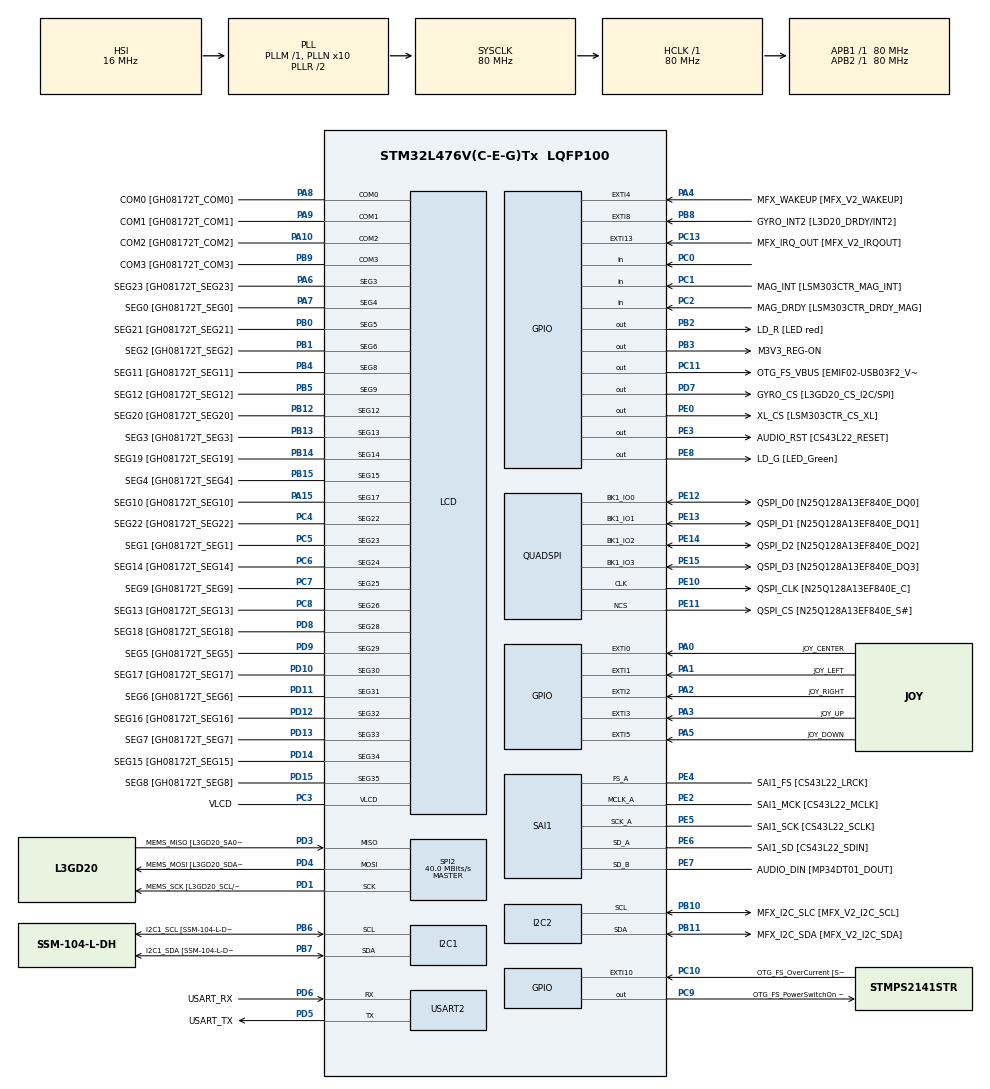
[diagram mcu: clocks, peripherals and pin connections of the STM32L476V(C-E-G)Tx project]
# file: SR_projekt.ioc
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I2C1.Timing=0x10909CEC
I2C2.Timing=0x10909CEC
LCD.Bias=LCD_BIAS_1_3
LCD.BlinkFrequency=LCD_BLINKFREQUENCY_DIV32
LCD.Contrast=LCD_CONTRASTLEVEL_5
LCD.Divider=LCD_DIVIDER_31
LCD.PulseOnDuration=LCD_PULSEONDURATION_4
Mcu.Family=STM32L4
Mcu.Name=STM32L476V(C-E-G)Tx
Mcu.Package=LQFP100
NVIC.EXTI0_IRQn=true\:0\:0\:false\:false\:true\:true\:true\:true
NVIC.EXTI1_IRQn=true\:0\:0\:false\:false\:true\:true\:true\:true
NVIC.EXTI2_IRQn=true\:0\:0\:false\:false\:true\:true\:true\:true
NVIC.EXTI3_IRQn=true\:0\:0\:false\:false\:true\:true\:true\:true
NVIC.EXTI9_5_IRQn=true\:0\:0\:false\:false\:true\:true\:true\:true
NVIC.PriorityGroup=NVIC_PRIORITYGROUP_4
NVIC.RCC_IRQn=true\:0\:0\:false\:false\:true\:true\:false\:true
PA0.GPIO_Label=JOY_CENTER
PA0.GPIO_ModeDefaultEXTI=GPIO_MODE_IT_RISING
PA0.GPIO_PuPd=GPIO_PULLDOWN
PA0.Signal=GPXTI0
PA1.GPIO_Label=JOY_LEFT
PA1.GPIO_ModeDefaultEXTI=GPIO_MODE_IT_RISING
PA1.GPIO_PuPd=GPIO_PULLDOWN
PA1.Signal=GPXTI1
PA10.GPIO_Label=COM2 [GH08172T_COM2]
PA10.GPIO_Mode=GPIO_MODE_AF_PP
PA10.GPIO_PuPd=GPIO_NOPULL
PA10.GPIO_Speed=GPIO_SPEED_FREQ_VERY_HIGH
PA10.Mode=1/4 Duty Cycle
PA10.Signal=LCD_COM2
PA11.GPIO_Label=OTG_FS_DM [EMIF02-USB03F2_D-out]
PA11.GPIO_Mode=GPIO_MODE_AF_PP
PA11.GPIO_PuPd=GPIO_NOPULL
PA11.GPIO_Speed=GPIO_SPEED_FREQ_VERY_HIGH
PA11.Signal=USB_OTG_FS_DM
PA12.GPIO_Label=OTG_FS_DP [EMIF02-USB03F2_D+out]
PA12.GPIO_Mode=GPIO_MODE_AF_PP
PA12.GPIO_PuPd=GPIO_NOPULL
PA12.GPIO_Speed=GPIO_SPEED_FREQ_VERY_HIGH
PA12.Signal=USB_OTG_FS_DP
PA13\ (JTMS-SWDIO).GPIO_Label=SWDIO
PA13\ (JTMS-SWDIO).Mode=Serial_Wire
PA13\ (JTMS-SWDIO).Signal=SYS_JTMS-SWDIO
PA14\ (JTCK-SWCLK).GPIO_Label=SWCLK
PA14\ (JTCK-SWCLK).Mode=Serial_Wire
PA14\ (JTCK-SWCLK).Signal=SYS_JTCK-SWCLK
PA15\ (JTDI).GPIO_Label=SEG10 [GH08172T_SEG10]
PA15\ (JTDI).GPIO_Mode=GPIO_MODE_AF_PP
PA15\ (JTDI).GPIO_PuPd=GPIO_NOPULL
PA15\ (JTDI).GPIO_Speed=GPIO_SPEED_FREQ_VERY_HIGH
PA15\ (JTDI).Mode=SEG17
PA15\ (JTDI).Signal=LCD_SEG17
PA2.GPIO_Label=JOY_RIGHT
PA2.GPIO_ModeDefaultEXTI=GPIO_MODE_IT_RISING
PA2.GPIO_PuPd=GPIO_PULLDOWN
PA2.Signal=GPXTI2
PA3.GPIO_Label=JOY_UP
PA3.GPIO_ModeDefaultEXTI=GPIO_MODE_IT_RISING
PA3.GPIO_PuPd=GPIO_PULLDOWN
PA3.Signal=GPXTI3
PA4.GPIO_Label=MFX_WAKEUP [MFX_V2_WAKEUP]
PA4.GPIO_ModeDefaultEXTI=GPIO_MODE_EVT_RISING
PA4.GPIO_PuPd=GPIO_NOPULL
PA4.Signal=GPXTI4
PA5.GPIO_Label=JOY_DOWN
PA5.GPIO_ModeDefaultEXTI=GPIO_MODE_IT_RISING
PA5.GPIO_PuPd=GPIO_PULLDOWN
PA5.Signal=GPXTI5
PA6.GPIO_Label=SEG23 [GH08172T_SEG23]
PA6.GPIO_Mode=GPIO_MODE_AF_PP
PA6.GPIO_PuPd=GPIO_NOPULL
PA6.GPIO_Speed=GPIO_SPEED_FREQ_VERY_HIGH
PA6.Mode=SEG3
PA6.Signal=LCD_SEG3
PA7.GPIO_Label=SEG0 [GH08172T_SEG0]
PA7.GPIO_Mode=GPIO_MODE_AF_PP
PA7.GPIO_PuPd=GPIO_NOPULL
PA7.GPIO_Speed=GPIO_SPEED_FREQ_VERY_HIGH
PA7.Mode=SEG4
PA7.Signal=LCD_SEG4
PA8.GPIO_Label=COM0 [GH08172T_COM0]
PA8.GPIO_Mode=GPIO_MODE_AF_PP
PA8.GPIO_PuPd=GPIO_NOPULL
PA8.GPIO_Speed=GPIO_SPEED_FREQ_VERY_HIGH
PA8.Mode=1/4 Duty Cycle
PA8.Signal=LCD_COM0
PA9.GPIO_Label=COM1 [GH08172T_COM1]
PA9.GPIO_Mode=GPIO_MODE_AF_PP
PA9.GPIO_PuPd=GPIO_NOPULL
PA9.GPIO_Speed=GPIO_SPEED_FREQ_VERY_HIGH
PA9.Mode=1/4 Duty Cycle
PA9.Signal=LCD_COM1
PB0.GPIO_Label=SEG21 [GH08172T_SEG21]
PB0.GPIO_Mode=GPIO_MODE_AF_PP
PB0.GPIO_PuPd=GPIO_NOPULL
PB0.GPIO_Speed=GPIO_SPEED_FREQ_VERY_HIGH
PB0.Mode=SEG5
PB0.Signal=LCD_SEG5
PB1.GPIO_Label=SEG2 [GH08172T_SEG2]
PB1.GPIO_Mode=GPIO_MODE_AF_PP
PB1.GPIO_PuPd=GPIO_NOPULL
PB1.GPIO_Speed=GPIO_SPEED_FREQ_VERY_HIGH
PB1.Mode=SEG6
PB1.Signal=LCD_SEG6
PB10.GPIO_Label=MFX_I2C_SLC [MFX_V2_I2C_SCL]
PB10.GPIO_Mode=GPIO_MODE_AF_OD
PB10.GPIO_Pu=GPIO_PULLUP
PB10.GPIO_Speed=GPIO_SPEED_FREQ_VERY_HIGH
PB10.Mode=I2C
PB10.Signal=I2C2_SCL
PB11.GPIO_Label=MFX_I2C_SDA [MFX_V2_I2C_SDA]
PB11.GPIO_Mode=GPIO_MODE_AF_OD
PB11.GPIO_Pu=GPIO_PULLUP
PB11.GPIO_Speed=GPIO_SPEED_FREQ_VERY_HIGH
PB11.Mode=I2C
PB11.Signal=I2C2_SDA
PB12.GPIO_Label=SEG20 [GH08172T_SEG20]
PB12.GPIO_Mode=GPIO_MODE_AF_PP
PB12.GPIO_PuPd=GPIO_NOPULL
PB12.GPIO_Speed=GPIO_SPEED_FREQ_VERY_HIGH
PB12.Mode=SEG12
PB12.Signal=LCD_SEG12
PB13.GPIO_Label=SEG3 [GH08172T_SEG3]
PB13.GPIO_Mode=GPIO_MODE_AF_PP
PB13.GPIO_PuPd=GPIO_NOPULL
PB13.GPIO_Speed=GPIO_SPEED_FREQ_VERY_HIGH
PB13.Mode=SEG13
PB13.Signal=LCD_SEG13
PB14.GPIO_Label=SEG19 [GH08172T_SEG19]
PB14.GPIO_Mode=GPIO_MODE_AF_PP
PB14.GPIO_PuPd=GPIO_NOPULL
PB14.GPIO_Speed=GPIO_SPEED_FREQ_VERY_HIGH
PB14.Mode=SEG14
PB14.Signal=LCD_SEG14
PB15.GPIO_Label=SEG4 [GH08172T_SEG4]
PB15.GPIO_Mode=GPIO_MODE_AF_PP
PB15.GPIO_PuPd=GPIO_NOPULL
PB15.GPIO_Speed=GPIO_SPEED_FREQ_VERY_HIGH
PB15.Mode=SEG15
PB15.Signal=LCD_SEG15
PB2.GPIO_Label=LD_R [LED red]
PB2.GPIO_ModeDefaultOutputPP=GPIO_MODE_OUTPUT_PP
PB2.GPIO_PuPd=GPIO_PULLUP
PB2.GPIO_Speed=GPIO_SPEED_FREQ_VERY_HIGH
PB2.Signal=GPIO_Output
PB3\ (JTDO-TRACESWO).GPIO_Label=M3V3_REG-ON
PB3\ (JTDO-TRACESWO).GPIO_ModeDefaultOutputPP=GPIO_MODE_OUTPUT_PP
PB3\ (JTDO-TRACESWO).GPIO_PuPd=GPIO_NOPULL
PB3\ (JTDO-TRACESWO).GPIO_Speed=GPIO_SPEED_FREQ_LOW
PB3\ (JTDO-TRACESWO).Signal=GPIO_Output
PB4\ (NJTRST).GPIO_Label=SEG11 [GH08172T_SEG11]
PB4\ (NJTRST).GPIO_Mode=GPIO_MODE_AF_PP
PB4\ (NJTRST).GPIO_PuPd=GPIO_NOPULL
PB4\ (NJTRST).GPIO_Speed=GPIO_SPEED_FREQ_VERY_HIGH
PB4\ (NJTRST).Mode=SEG8
PB4\ (NJTRST).Signal=LCD_SEG8
PB5.GPIO_Label=SEG12 [GH08172T_SEG12]
PB5.GPIO_Mode=GPIO_MODE_AF_PP
PB5.GPIO_PuPd=GPIO_NOPULL
PB5.GPIO_Speed=GPIO_SPEED_FREQ_VERY_HIGH
PB5.Mode=SEG9
PB5.Signal=LCD_SEG9
PB6.GPIO_FM6=__NULL
PB6.GPIO_Label=I2C1_SCL [SSM-104-L-DH_SCL]
PB6.GPIO_Mode=GPIO_MODE_AF_OD
PB6.GPIO_Pu=GPIO_PULLUP
PB6.GPIO_Speed=GPIO_SPEED_FREQ_VERY_HIGH
PB6.Mode=I2C
PB6.Signal=I2C1_SCL
PB7.GPIO_FM7=__NULL
PB7.GPIO_Label=I2C1_SDA [SSM-104-L-DH_SDA]
PB7.GPIO_Mode=GPIO_MODE_AF_OD
PB7.GPIO_Pu=GPIO_PULLUP
PB7.GPIO_Speed=GPIO_SPEED_FREQ_VERY_HIGH
PB7.Mode=I2C
PB7.Signal=I2C1_SDA
PB8.GPIO_Label=GYRO_INT2 [L3D20_DRDY/INT2]
PB8.GPIO_ModeDefaultEXTI=GPIO_MODE_EVT_RISING
PB8.GPIO_PuPd=GPIO_NOPULL
PB8.Signal=GPXTI8
PB9.GPIO_FM9=__NULL
PB9.GPIO_Label=COM3 [GH08172T_COM3]
PB9.GPIO_Mode=GPIO_MODE_AF_PP
PB9.GPIO_PuPd=GPIO_NOPULL
PB9.GPIO_Speed=GPIO_SPEED_FREQ_VERY_HIGH
PB9.Mode=1/4 Duty Cycle
PB9.Signal=LCD_COM3
PC0.Signal=GPIO_Input
PC1.GPIO_Label=MAG_INT [LSM303CTR_MAG_INT]
PC1.GPIO_Mode=GPIO_MODE_INPUT
PC1.GPIO_PuPd=GPIO_NOPULL
PC1.Signal=GPIO_Input
PC10.GPIO_Label=OTG_FS_OverCurrent [STMPS2141STR_FAULT]
PC10.GPIO_ModeDefaultEXTI=GPIO_MODE_EVT_RISING
PC10.GPIO_PuPd=GPIO_NOPULL
PC10.Signal=GPXTI10
PC11.GPIO_Label=OTG_FS_VBUS [EMIF02-USB03F2_Vbus]
PC11.GPIO_ModeDefaultOutputPP=GPIO_MODE_OUTPUT_PP
PC11.GPIO_PuPd=GPIO_NOPULL
PC11.GPIO_Speed=GPIO_SPEED_FREQ_LOW
PC11.Signal=GPIO_Output
PC13.GPIO_Label=MFX_IRQ_OUT [MFX_V2_IRQOUT]
PC13.GPIO_ModeDefaultEXTI=GPIO_MODE_EVT_RISING
PC13.GPIO_PuPd=GPIO_NOPULL
PC13.Signal=GPXTI13
PC14-OSC32_IN\ (PC14).Mode=LSE-External-Oscillator
PC14-OSC32_IN\ (PC14).Signal=RCC_OSC32_IN
PC15-OSC32_OUT\ (PC15).Mode=LSE-External-Oscillator
PC15-OSC32_OUT\ (PC15).Signal=RCC_OSC32_OUT
PC2.GPIO_Label=MAG_DRDY [LSM303CTR_DRDY_MAG]
PC2.GPIO_Mode=GPIO_MODE_INPUT
PC2.GPIO_PuPd=GPIO_NOPULL
PC2.Signal=GPIO_Input
PC3.GPIO_Label=VLCD
PC3.GPIO_Mode=GPIO_MODE_AF_PP
PC3.GPIO_PuPd=GPIO_NOPULL
PC3.GPIO_Speed=GPIO_SPEED_FREQ_VERY_HIGH
PC3.Mode=1/4 Duty Cycle
PC3.Signal=LCD_VLCD
PC4.GPIO_Label=SEG22 [GH08172T_SEG22]
PC4.GPIO_Mode=GPIO_MODE_AF_PP
PC4.GPIO_PuPd=GPIO_NOPULL
PC4.GPIO_Speed=GPIO_SPEED_FREQ_VERY_HIGH
PC4.Mode=SEG22
PC4.Signal=LCD_SEG22
PC5.GPIO_Label=SEG1 [GH08172T_SEG1]
PC5.GPIO_Mode=GPIO_MODE_AF_PP
PC5.GPIO_PuPd=GPIO_NOPULL
PC5.GPIO_Speed=GPIO_SPEED_FREQ_VERY_HIGH
PC5.Mode=SEG23
PC5.Signal=LCD_SEG23
PC6.GPIO_Label=SEG14 [GH08172T_SEG14]
PC6.GPIO_Mode=GPIO_MODE_AF_PP
PC6.GPIO_PuPd=GPIO_NOPULL
PC6.GPIO_Speed=GPIO_SPEED_FREQ_VERY_HIGH
PC6.Mode=SEG24
PC6.Signal=LCD_SEG24
PC7.GPIO_Label=SEG9 [GH08172T_SEG9]
PC7.GPIO_Mode=GPIO_MODE_AF_PP
PC7.GPIO_PuPd=GPIO_NOPULL
PC7.GPIO_Speed=GPIO_SPEED_FREQ_VERY_HIGH
PC7.Mode=SEG25
PC7.Signal=LCD_SEG25
PC8.GPIO_Label=SEG13 [GH08172T_SEG13]
PC8.GPIO_Mode=GPIO_MODE_AF_PP
PC8.GPIO_PuPd=GPIO_NOPULL
PC8.GPIO_Speed=GPIO_SPEED_FREQ_VERY_HIGH
PC8.Mode=SEG26
PC8.Signal=LCD_SEG26
PC9.GPIO_Label=OTG_FS_PowerSwitchOn [STMPS2141STR_EN]
PC9.GPIO_ModeDefaultOutputPP=GPIO_MODE_OUTPUT_PP
PC9.GPIO_PuPd=GPIO_NOPULL
PC9.GPIO_Speed=GPIO_SPEED_FREQ_LOW
PC9.PinState=GPIO_PIN_SET
PC9.Signal=GPIO_Output
PD1.GPIO_Label=MEMS_SCK [L3GD20_SCL/SPC]
PD1.GPIO_Mode=GPIO_MODE_AF_PP
PD1.GPIO_PuPd=GPIO_NOPULL
PD1.GPIO_Speed=GPIO_SPEED_FREQ_VERY_HIGH
PD1.Mode=Full_Duplex_Master
PD1.Signal=SPI2_SCK
PD10.GPIO_Label=SEG17 [GH08172T_SEG17]
PD10.GPIO_Mode=GPIO_MODE_AF_PP
PD10.GPIO_PuPd=GPIO_NOPULL
PD10.GPIO_Speed=GPIO_SPEED_FREQ_VERY_HIGH
PD10.Mode=SEG30
PD10.Signal=LCD_SEG30
PD11.GPIO_Label=SEG6 [GH08172T_SEG6]
PD11.GPIO_Mode=GPIO_MODE_AF_PP
PD11.GPIO_PuPd=GPIO_NOPULL
PD11.GPIO_Speed=GPIO_SPEED_FREQ_VERY_HIGH
PD11.Mode=SEG31
PD11.Signal=LCD_SEG31
PD12.GPIO_Label=SEG16 [GH08172T_SEG16]
PD12.GPIO_Mode=GPIO_MODE_AF_PP
PD12.GPIO_PuPd=GPIO_NOPULL
PD12.GPIO_Speed=GPIO_SPEED_FREQ_VERY_HIGH
PD12.Mode=SEG32
PD12.Signal=LCD_SEG32
PD13.GPIO_Label=SEG7 [GH08172T_SEG7]
PD13.GPIO_Mode=GPIO_MODE_AF_PP
PD13.GPIO_PuPd=GPIO_NOPULL
PD13.GPIO_Speed=GPIO_SPEED_FREQ_VERY_HIGH
PD13.Mode=SEG33
PD13.Signal=LCD_SEG33
PD14.GPIO_Label=SEG15 [GH08172T_SEG15]
PD14.GPIO_Mode=GPIO_MODE_AF_PP
PD14.GPIO_PuPd=GPIO_NOPULL
PD14.GPIO_Speed=GPIO_SPEED_FREQ_VERY_HIGH
PD14.Mode=SEG34
PD14.Signal=LCD_SEG34
PD15.GPIO_Label=SEG8 [GH08172T_SEG8]
PD15.GPIO_Mode=GPIO_MODE_AF_PP
PD15.GPIO_PuPd=GPIO_NOPULL
PD15.GPIO_Speed=GPIO_SPEED_FREQ_VERY_HIGH
PD15.Mode=SEG35
PD15.Signal=LCD_SEG35
PD3.GPIO_Label=MEMS_MISO [L3GD20_SA0/SDO]
PD3.GPIO_Mode=GPIO_MODE_AF_PP
PD3.GPIO_PuPd=GPIO_NOPULL
PD3.GPIO_Speed=GPIO_SPEED_FREQ_VERY_HIGH
PD3.Mode=Full_Duplex_Master
PD3.Signal=SPI2_MISO
PD4.GPIO_Label=MEMS_MOSI [L3GD20_SDA/SDI/SDO]
PD4.GPIO_Mode=GPIO_MODE_AF_PP
PD4.GPIO_PuPd=GPIO_NOPULL
PD4.GPIO_Speed=GPIO_SPEED_FREQ_VERY_HIGH
PD4.Mode=Full_Duplex_Master
PD4.Signal=SPI2_MOSI
PD5.GPIO_Label=USART_TX
PD5.GPIO_Mode=GPIO_MODE_AF_PP
PD5.GPIO_PuPd=GPIO_PULLUP
PD5.GPIO_Speed=GPIO_SPEED_FREQ_VERY_HIGH
PD5.Mode=Asynchronous
PD5.Signal=USART2_TX
PD6.GPIO_Label=USART_RX
PD6.GPIO_Mode=GPIO_MODE_AF_PP
PD6.GPIO_PuPd=GPIO_PULLUP
PD6.GPIO_Speed=GPIO_SPEED_FREQ_VERY_HIGH
PD6.Mode=Asynchronous
PD6.Signal=USART2_RX
PD7.GPIO_Label=GYRO_CS [L3GD20_CS_I2C/SPI]
PD7.GPIO_ModeDefaultOutputPP=GPIO_MODE_OUTPUT_PP
PD7.GPIO_PuPd=GPIO_NOPULL
PD7.GPIO_Speed=GPIO_SPEED_FREQ_VERY_HIGH
PD7.Signal=GPIO_Output
PD8.GPIO_Label=SEG18 [GH08172T_SEG18]
PD8.GPIO_Mode=GPIO_MODE_AF_PP
PD8.GPIO_PuPd=GPIO_NOPULL
PD8.GPIO_Speed=GPIO_SPEED_FREQ_VERY_HIGH
PD8.Mode=SEG28
PD8.Signal=LCD_SEG28
PD9.GPIO_Label=SEG5 [GH08172T_SEG5]
PD9.GPIO_Mode=GPIO_MODE_AF_PP
PD9.GPIO_PuPd=GPIO_NOPULL
PD9.GPIO_Speed=GPIO_SPEED_FREQ_VERY_HIGH
PD9.Mode=SEG29
PD9.Signal=LCD_SEG29
PE0.GPIO_Label=XL_CS [LSM303CTR_CS_XL]
PE0.GPIO_ModeDefaultOutputPP=GPIO_MODE_OUTPUT_PP
PE0.GPIO_PuPd=GPIO_NOPULL
PE0.GPIO_Speed=GPIO_SPEED_FREQ_LOW
PE0.Signal=GPIO_Output
PE10.GPIO_Label=QSPI_CLK [N25Q128A13EF840E_C]
PE10.GPIO_Mode=GPIO_MODE_AF_PP
PE10.GPIO_PuPd=GPIO_NOPULL
PE10.GPIO_Speed=GPIO_SPEED_FREQ_VERY_HIGH
PE10.Mode=Single Bank
PE10.Signal=QUADSPI_CLK
PE11.GPIO_Label=QSPI_CS [N25Q128A13EF840E_S\#]
PE11.GPIO_Mode=GPIO_MODE_AF_PP
PE11.GPIO_PuPd=GPIO_PULLUP
PE11.GPIO_Speed=GPIO_SPEED_FREQ_VERY_HIGH
PE11.Mode=Single Bank
PE11.Signal=QUADSPI_NCS
PE12.GPIO_Label=QSPI_D0 [N25Q128A13EF840E_DQ0]
PE12.GPIO_Mode=GPIO_MODE_AF_PP
PE12.GPIO_PuPd=GPIO_NOPULL
PE12.GPIO_Speed=GPIO_SPEED_FREQ_VERY_HIGH
PE12.Mode=Single Bank
PE12.Signal=QUADSPI_BK1_IO0
PE13.GPIO_Label=QSPI_D1 [N25Q128A13EF840E_DQ1]
PE13.GPIO_Mode=GPIO_MODE_AF_PP
PE13.GPIO_PuPd=GPIO_NOPULL
PE13.GPIO_Speed=GPIO_SPEED_FREQ_VERY_HIGH
PE13.Mode=Single Bank
PE13.Signal=QUADSPI_BK1_IO1
PE14.GPIO_Label=QSPI_D2 [N25Q128A13EF840E_DQ2]
PE14.GPIO_Mode=GPIO_MODE_AF_PP
PE14.GPIO_PuPd=GPIO_NOPULL
PE14.GPIO_Speed=GPIO_SPEED_FREQ_VERY_HIGH
PE14.Mode=Single Bank
PE14.Signal=QUADSPI_BK1_IO2
PE15.GPIO_Label=QSPI_D3 [N25Q128A13EF840E_DQ3]
PE15.GPIO_Mode=GPIO_MODE_AF_PP
PE15.GPIO_PuPd=GPIO_NOPULL
PE15.GPIO_Speed=GPIO_SPEED_FREQ_VERY_HIGH
PE15.Mode=Single Bank
PE15.Signal=QUADSPI_BK1_IO3
PE2.GPIO_Label=SAI1_MCK [CS43L22_MCLK]
PE2.GPIO_Mode=GPIO_MODE_AF_PP
PE2.GPIO_PuPd=GPIO_NOPULL
PE2.GPIO_Speed=GPIO_SPEED_FREQ_VERY_HIGH
PE2.Mode=SAI_A_MasterWithClock
PE2.Signal=SAI1_MCLK_A
PE3.GPIO_Label=AUDIO_RST [CS43L22_RESET]
PE3.GPIO_ModeDefaultOutputPP=GPIO_MODE_OUTPUT_PP
PE3.GPIO_PuPd=GPIO_NOPULL
PE3.GPIO_Speed=GPIO_SPEED_FREQ_HIGH
PE3.Signal=GPIO_Output
PE4.GPIO_Label=SAI1_FS [CS43L22_LRCK]
PE4.GPIO_Mode=GPIO_MODE_AF_PP
PE4.GPIO_PuPd=GPIO_NOPULL
PE4.GPIO_Speed=GPIO_SPEED_FREQ_VERY_HIGH
PE4.Mode=SAI_A_MasterWithClock
PE4.Signal=SAI1_FS_A
PE5.GPIO_Label=SAI1_SCK [CS43L22_SCLK]
PE5.GPIO_Mode=GPIO_MODE_AF_PP
PE5.GPIO_PuPd=GPIO_NOPULL
PE5.GPIO_Speed=GPIO_SPEED_FREQ_VERY_HIGH
PE5.Mode=SAI_A_MasterWithClock
PE5.Signal=SAI1_SCK_A
PE6.GPIO_Label=SAI1_SD [CS43L22_SDIN]
PE6.GPIO_Mode=GPIO_MODE_AF_PP
PE6.GPIO_PuPd=GPIO_NOPULL
PE6.GPIO_Speed=GPIO_SPEED_FREQ_VERY_HIGH
PE6.Mode=SAI_A_MasterWithClock
PE6.Signal=SAI1_SD_A
PE7.GPIO_Label=AUDIO_DIN [MP34DT01_DOUT]
PE7.GPIO_Mode=GPIO_MODE_AF_PP
PE7.GPIO_PuPd=GPIO_NOPULL
PE7.GPIO_Speed=GPIO_SPEED_FREQ_VERY_HIGH
PE7.Mode=SAI_B_SyncSlave
PE7.Signal=SAI1_SD_B
PE8.GPIO_Label=LD_G [LED_Green]
PE8.GPIO_ModeDefaultOutputPP=GPIO_MODE_OUTPUT_PP
PE8.GPIO_PuPd=GPIO_PULLUP
PE8.GPIO_Speed=GPIO_SPEED_FREQ_VERY_HIGH
PE8.Signal=GPIO_Output
PE9.GPIO_Label=AUDIO_CLK [MP34DT01_CLK]
PE9.GPIO_Mode=GPIO_MODE_AF_PP
PE9.GPIO_PuPd=GPIO_NOPULL
PE9.GPIO_Speed=GPIO_SPEED_FREQ_LOW
PE9.Signal=SAI1_FS_B
PH0-OSC_IN\ (PH0).Mode=HSE-External-Oscillator
PH0-OSC_IN\ (PH0).Signal=RCC_OSC_IN
PH1-OSC_OUT\ (PH1).Mode=HSE-External-Oscillator
PH1-OSC_OUT\ (PH1).Signal=RCC_OSC_OUT
ProjectManager.HeapSize=0x200
ProjectManager.StackSize=0x400
ProjectManager.TargetToolchain=STM32CubeIDE
QUADSPI.ClockPrescaler=1
QUADSPI.FifoThreshold=4
QUADSPI.FlashSize=24
QUADSPI.FlashSize-Single\ Bank=16
QUADSPI.SampleShifting=QSPI_SAMPLE_SHIFTING_HALFCYCLE
RCC.ADCFreq_Value=64000000
RCC.AHBFreq_Value=80000000
RCC.APB1Freq_Value=80000000
RCC.APB1TimFreq_Value=80000000
RCC.APB2Freq_Value=80000000
RCC.APB2TimFreq_Value=80000000
RCC.CortexFreq_Value=80000000
RCC.HCLKFreq_Value=80000000
RCC.HSE_VALUE=8000000
RCC.HSI_VALUE=16000000
RCC.MSI_VALUE=4000000
RCC.PLLN=10
RCC.PLLSourceVirtual=RCC_PLLSOURCE_HSI
RCC.PREFETCH_ENABLE=1
RCC.RTCClockSelection=RCC_RTCCLKSOURCE_LSE
RCC.SYSCLKFreq_VALUE=80000000
RCC.SYSCLKSource=RCC_SYSCLKSOURCE_PLLCLK
RCC.USBFreq_Value=64000000
RCC.VCOOutputFreq_Value=160000000
RTC.Date=19
RTC.Month=RTC_MONTH_MARCH
RTC.WeekDay=RTC_WEEKDAY_SATURDAY
RTC.Year=22
SAI1.ErrorAudioFreq-SAI_A_MasterWithClock=-62.79 %
SAI1.Instance-SAI_A_MasterWithClock=SAI$Index_Block_A
SAI1.Instance-SAI_B_SyncSlave=SAI$Index_Block_B
SAI1.MClockEnable-SAI_A_MasterWithClock=SAI_MASTERCLOCK_ENABLE
SAI1.RealAudioFreq-SAI_A_MasterWithClock=71.428 KHz
SAI1.Synchro-SAI_B_SyncSlave=SAI_SYNCHRONOUS
SAI1.VirtualMode-SAI_A_MasterWithClock=VM_MASTER
SAI1.VirtualMode-SAI_B_SyncSlave=VM_SLAVE
SPI2.BaudRatePrescaler=SPI_BAUDRATEPRESCALER_2
SPI2.CalculateBaudRate=40.0 MBits/s
SPI2.Direction=SPI_DIRECTION_2LINES
SPI2.Mode=SPI_MODE_MASTER
SPI2.VirtualType=VM_MASTER
USART2.VirtualMode-Asynchronous=VM_ASYNC
VP_IWDG_VS_IWDG.Mode=IWDG_Activate
VP_RTC_VS_RTC_Activate.Mode=RTC_Enabled
VP_RTC_VS_RTC_Calendar.Mode=RTC_Calendar
board=STM32L476G-DISCO

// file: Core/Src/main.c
/* USER CODE BEGIN Header */
/**
 ******************************************************************************
 * @file           : main.c
 * @brief          : Main program body
 ******************************************************************************
 * @attention
 *
 * Copyright (c) 2022 STMicroelectronics.
 * All rights reserved.
 *
 * This software is licensed under terms that can be found in the LICENSE file
 * in the root directory of this software component.
 * If no LICENSE file comes with this software, it is provided AS-IS.
 *
 ******************************************************************************
 */
/* USER CODE END Header */
#include "main.h"
#include "i2c.h"
#include "iwdg.h"
#include "lcd.h"
#include "quadspi.h"
#include "rtc.h"
#include "sai.h"
#include "spi.h"
#include "usart.h"
#include "gpio.h"

/* USER CODE BEGIN Includes */
#include "stdbool.h"
#include "string.h"
#include "lfs.h"
#include "stm32l476g_discovery_qspi.h"
#include "lsm303c.h"
#include "math.h"
#include <stdio.h>
#include <stdbool.h>
/* USER CODE END Includes */

/* USER CODE BEGIN PV */
lfs_t lfs;
lfs_file_t file;
volatile JOYState_TypeDef joy_state = JOY_NONE;
volatile FlagStatus KeyPressed = RESET;
/* USER CODE END PV */

void SystemClock_Config(void);
void PeriphCommonClock_Config(void);
/* USER CODE BEGIN PFP */
void HAL_GPIO_EXTI_Callback(uint16_t GPIO_Pin);
int block_device_read(const struct lfs_config *c, lfs_block_t block, lfs_off_t off, void *buffer, lfs_size_t size);
int block_device_prog(const struct lfs_config *c, lfs_block_t block, lfs_off_t off, const void *buffer, lfs_size_t size);
int block_device_erase(const struct lfs_config *c, lfs_block_t block);
int block_device_sync(const struct lfs_config *c);

void readFile(lfs_t *lfs, lfs_file_t *file, const char *path, void *buffer, lfs_size_t size);
void writeFile(lfs_t *lfs, lfs_file_t *file, const char *path, const void *buffer, lfs_size_t size);
static int traverse_df_cb(void *p, lfs_block_t block);
static int df(void);
int16_t GetTemperature();
void initMagneto();
void initFileSystem(int *number_of_records, uint32_t *delay_between_saves);
float convertRegDataToTemperature(int16_t value);
float getTemperatureCelsius();
void menu(int *menu_position, char *text, int *menu_select, int *i, bool erase_flag);
void menuUserView(int choose, char *text);
void setDateUserView(int choose, RTC_TimeTypeDef time, RTC_DateTypeDef date, char *text);
void changeDateDown(int choose, RTC_TimeTypeDef *time, RTC_DateTypeDef *date);
void changeDateUp(int choose, RTC_TimeTypeDef *time, RTC_DateTypeDef *date);
void timeUserView(int choose, RTC_TimeTypeDef *time, char *text);
void changeTimeDown(int choose, RTC_TimeTypeDef *time);
void changeTimeUp(int choose, RTC_TimeTypeDef *time);
void setDelayBetweenSaves(uint32_t *delay_between_saves, RTC_TimeTypeDef *time);
bool eraseAllData(int *number_of_records, int *read_record_number, uint32_t *delay_between_saves);
void viewActualData(RTC_TimeTypeDef *RtcTime, RTC_DateTypeDef *RtcDate, char *text);
void saveData(RTC_TimeTypeDef *RtcTime, RTC_DateTypeDef *RtcDate, int *number_of_records);
void setTimeBetweenSaves(RTC_TimeTypeDef *time, uint32_t delay);
/* USER CODE END PFP */

/* USER CODE BEGIN 0 */
const struct lfs_config cfg = {
    // block device operations
    .read = block_device_read,
    .prog = block_device_prog,
    .erase = block_device_erase,
    .sync = block_device_sync,

    // block device configuration
    .read_size = 16,
    .prog_size = 16,
    .block_size = 4096,
    .block_count = 4096,
    .cache_size = 16,
    .lookahead_size = 16,
    .block_cycles = 500,
};
/* USER CODE END 0 */

int main(void)
{
    /* USER CODE BEGIN 1 */
    uint32_t last_ms = HAL_GetTick(), last_ms_save = last_ms, now = last_ms, delay_text_scroll = 200, delay_between_saves = 3600000; // delays in ms; delay between saves is one hour
    int i = 0, menu_position = 0, menu_select = 0, set_time_tmp = -1, number_of_records = 0, read_record_number = 0;
    char text[60], display[6], record_file_name[15];
    bool erase_flag = false, new_data = false;
    RTC_TimeTypeDef RtcTime = {0}, new_time = {0}, time_between_saves = {0};
    RTC_DateTypeDef RtcDate = {0}, new_date = {0};
    /* USER CODE END 1 */

    /* MCU Configuration--------------------------------------------------------*/

    /* Reset of all peripherals, Initializes the Flash interface and the Systick. */
    HAL_Init();

    /* Configure the system clock */
    SystemClock_Config();

    /* Configure the peripherals common clocks */
    PeriphCommonClock_Config();

    /* Initialize all configured peripherals */
    MX_GPIO_Init();
    MX_I2C1_Init();
    MX_I2C2_Init();
    // MX_LCD_Init();
    // MX_QUADSPI_Init();
    MX_SAI1_Init();
    MX_SPI2_Init();
    MX_USART2_UART_Init();
    MX_RTC_Init();
    MX_IWDG_Init();
    /* USER CODE BEGIN 2 */
    BSP_LCD_GLASS_Init();
    BSP_QSPI_Init();
    initMagneto();
    initFileSystem(&number_of_records, &delay_between_saves);
    HAL_RTC_GetTime(&hrtc, &RtcTime, RTC_FORMAT_BIN);
    HAL_RTC_GetDate(&hrtc, &RtcDate, RTC_FORMAT_BIN);

    read_record_number = number_of_records;
    setTimeBetweenSaves(&time_between_saves, delay_between_saves);

    sprintf(text, "UZYJ JOYSTICKA ABY NAWIGOWAC      ");
    /* USER CODE END 2 */

    /* Infinite loop */
    /* USER CODE BEGIN WHILE */
    while (1)
    {
        now = HAL_GetTick();

        if (KeyPressed)
        {
            menu(&menu_position, text, &menu_select, &i, erase_flag);
        }

        if (i <= strlen(text))
        {
            if (now - last_ms >= delay_text_scroll)
            {
                last_ms = now;

                switch (menu_select)
                {
                case 1:
                    viewActualData(&RtcTime, &RtcDate, text);
                    break;
                case 2:
                    if (number_of_records)
                    {
                        if (new_data)
                        {
                            i = 0;
                            new_data = false;
                        }
                        switch (joy_state)
                        {
                        case JOY_RIGHT:
                            if (!erase_flag)
                            {
                                erase_flag = true;
                                i = 0;
                            }

                            break;
                        case JOY_LEFT:
                            if (erase_flag)
                            {
                                erase_flag = false;
                                i = 0;
                            }
                            break;
                        case JOY_SEL:
                            if (erase_flag)
                            {
                                erase_flag = eraseAllData(&number_of_records, &read_record_number, &delay_between_saves);
                            }

                            break;
                        case JOY_UP:
                            read_record_number++;
                            if (read_record_number > number_of_records)
                            {
                                read_record_number = 1;
                            }
                            i = 0;
                            break;
                        case JOY_DOWN:
                            read_record_number--;
                            if (read_record_number < 1)
                            {
                                read_record_number = number_of_records;
                            }
                            i = 0;
                            break;
                        default:
                            break;
                        }
                        joy_state = JOY_NONE;
                        if (!erase_flag)
                        {
                            sprintf(record_file_name, "record%d", read_record_number);
                            readFile(&lfs, &file, record_file_name, &text, sizeof(text));
                        }
                        else
                        {
                            sprintf(text, "POTWIERDZ USUNIECIE DANYCH      ");
                        }
                    }
                    else
                    {
                        new_data = true;
                        sprintf(text, "BRAK ZAPISANYCH DANYCH      ");
                    }
                    break;
                case 3:
                    switch (joy_state)
                    {
                    case JOY_SEL:
                        set_time_tmp++;
                        break;
                    case JOY_UP:
                        changeDateUp(set_time_tmp, &new_time, &new_date);
                        break;
                    case JOY_DOWN:
                        changeDateDown(set_time_tmp, &new_time, &new_date);
                        break;
                    default:
                        break;
                    }
                    setDateUserView(set_time_tmp, new_time, new_date, text);
                    if (set_time_tmp <= 5)
                    {
                        joy_state = JOY_NONE;
                    }
                    else
                    {
                        HAL_RTC_SetTime(&hrtc, &new_time, RTC_FORMAT_BIN);
                        HAL_RTC_SetDate(&hrtc, &new_date, RTC_FORMAT_BIN);
                        joy_state = JOY_LEFT;
                        KeyPressed = SET;
                    }
                    break;
                case 4:
                    switch (joy_state)
                    {
                    case JOY_SEL:
                        set_time_tmp++;
                        if (time_between_saves.Hours == 0 && time_between_saves.Minutes == 0 && time_between_saves.Seconds == 0 && set_time_tmp == 2)
                        {
                            time_between_saves.Seconds = 1;
                        }
                        break;
                    case JOY_UP:
                        changeTimeUp(set_time_tmp, &time_between_saves);
                        break;
                    case JOY_DOWN:
                        changeTimeDown(set_time_tmp, &time_between_saves);
                        break;
                    default:
                        break;
                    }

                    timeUserView(set_time_tmp, &time_between_saves, text);

                    if (set_time_tmp <= 2)
                    {
                        joy_state = JOY_NONE;
                    }
                    else
                    {
                        setDelayBetweenSaves(&delay_between_saves, &time_between_saves);
                        joy_state = JOY_LEFT;
                        KeyPressed = SET;
                    }
                    break;
                default:
                    read_record_number = number_of_records;
                    set_time_tmp = -1;
                    new_time = RtcTime;
                    new_date = RtcDate;
                    menuUserView(menu_position, text);
                    break;
                }

                if (menu_select < 3)
                {
                    for (int j = i - 6; j < i; j++)
                    {
                        if (j < 0)
                        {
                            display[j - i + 6] = text[strlen(text) + j];
                        }
                        else
                        {
                            display[j - i + 6] = text[j];
                        }
                    }
                    i++;
                    BSP_LCD_GLASS_Clear();
                    BSP_LCD_GLASS_DisplayString((uint8_t *)display);
                }
                else
                {
                    BSP_LCD_GLASS_Clear();
                    BSP_LCD_GLASS_DisplayString((uint8_t *)text);
                }
                BSP_LCD_GLASS_DisplayBar(LCD_BAR_3 >> (menu_position - 1));
            }

            if (now - last_ms_save >= delay_between_saves)
            {
                last_ms_save = now;
                saveData(&RtcTime, &RtcDate, &number_of_records);
            }
        }
        else
        {
            i = 0;
        }

        HAL_IWDG_Refresh(&hiwdg);
        /* USER CODE END WHILE */

    }
}

void SystemClock_Config(void)
{
    RCC_OscInitTypeDef RCC_OscInitStruct = {0};
    RCC_ClkInitTypeDef RCC_ClkInitStruct = {0};

    /** Configure the main internal regulator output voltage
     */
    if (HAL_PWREx_ControlVoltageScaling(PWR_REGULATOR_VOLTAGE_SCALE1) != HAL_OK)
    {
        Error_Handler();
    }

    /** Configure LSE Drive Capability
     */
    HAL_PWR_EnableBkUpAccess();
    __HAL_RCC_LSEDRIVE_CONFIG(RCC_LSEDRIVE_LOW);

    /** Initializes the RCC Oscillators according to the specified parameters
     * in the RCC_OscInitTypeDef structure.
     */
    RCC_OscInitStruct.OscillatorType = RCC_OSCILLATORTYPE_HSI | RCC_OSCILLATORTYPE_LSI | RCC_OSCILLATORTYPE_LSE;
    RCC_OscInitStruct.LSEState = RCC_LSE_ON;
    RCC_OscInitStruct.HSIState = RCC_HSI_ON;
    RCC_OscInitStruct.HSICalibrationValue = RCC_HSICALIBRATION_DEFAULT;
    RCC_OscInitStruct.LSIState = RCC_LSI_ON;
    RCC_OscInitStruct.PLL.PLLState = RCC_PLL_ON;
    RCC_OscInitStruct.PLL.PLLSource = RCC_PLLSOURCE_HSI;
    RCC_OscInitStruct.PLL.PLLM = 1;
    RCC_OscInitStruct.PLL.PLLN = 10;
    RCC_OscInitStruct.PLL.PLLP = RCC_PLLP_DIV7;
    RCC_OscInitStruct.PLL.PLLQ = RCC_PLLQ_DIV2;
    RCC_OscInitStruct.PLL.PLLR = RCC_PLLR_DIV2;
    if (HAL_RCC_OscConfig(&RCC_OscInitStruct) != HAL_OK)
    {
        Error_Handler();
    }

    /** Initializes the CPU, AHB and APB buses clocks
     */
    RCC_ClkInitStruct.ClockType = RCC_CLOCKTYPE_HCLK | RCC_CLOCKTYPE_SYSCLK | RCC_CLOCKTYPE_PCLK1 | RCC_CLOCKTYPE_PCLK2;
    RCC_ClkInitStruct.SYSCLKSource = RCC_SYSCLKSOURCE_PLLCLK;
    RCC_ClkInitStruct.AHBCLKDivider = RCC_SYSCLK_DIV1;
    RCC_ClkInitStruct.APB1CLKDivider = RCC_HCLK_DIV1;
    RCC_ClkInitStruct.APB2CLKDivider = RCC_HCLK_DIV1;

    if (HAL_RCC_ClockConfig(&RCC_ClkInitStruct, FLASH_LATENCY_4) != HAL_OK)
    {
        Error_Handler();
    }
}

void PeriphCommonClock_Config(void)
{
    RCC_PeriphCLKInitTypeDef PeriphClkInit = {0};

    /** Initializes the peripherals clock
     */
    PeriphClkInit.PeriphClockSelection = RCC_PERIPHCLK_SAI1;
    PeriphClkInit.Sai1ClockSelection = RCC_SAI1CLKSOURCE_PLLSAI1;
    PeriphClkInit.PLLSAI1.PLLSAI1Source = RCC_PLLSOURCE_HSI;
    PeriphClkInit.PLLSAI1.PLLSAI1M = 1;
    PeriphClkInit.PLLSAI1.PLLSAI1N = 8;
    PeriphClkInit.PLLSAI1.PLLSAI1P = RCC_PLLP_DIV7;
    PeriphClkInit.PLLSAI1.PLLSAI1Q = RCC_PLLQ_DIV2;
    PeriphClkInit.PLLSAI1.PLLSAI1R = RCC_PLLR_DIV2;
    PeriphClkInit.PLLSAI1.PLLSAI1ClockOut = RCC_PLLSAI1_SAI1CLK;
    if (HAL_RCCEx_PeriphCLKConfig(&PeriphClkInit) != HAL_OK)
    {
        Error_Handler();
    }
}

/* USER CODE BEGIN 4 */
void HAL_GPIO_EXTI_Callback(uint16_t GPIO_Pin)
{
    if ((GPIO_Pin & (DOWN_JOY_PIN | UP_JOY_PIN | SEL_JOY_PIN | RIGHT_JOY_PIN | LEFT_JOY_PIN)) != RESET)
    {
        KeyPressed = SET;

        switch (GPIO_Pin)
        {
        case DOWN_JOY_PIN:
            joy_state = JOY_DOWN;
            break;
        case UP_JOY_PIN:
            joy_state = JOY_UP;
            break;
        case SEL_JOY_PIN:
            joy_state = JOY_SEL;
            break;
        case RIGHT_JOY_PIN:
            joy_state = JOY_RIGHT;
            break;
        case LEFT_JOY_PIN:
            joy_state = JOY_LEFT;
            break;
        }
    }
}

int block_device_read(const struct lfs_config *c, lfs_block_t block, lfs_off_t off, void *buffer, lfs_size_t size)
{
    BSP_QSPI_Read((uint8_t *)buffer, (block * c->block_size + off), size);
    return 0;
}

int block_device_prog(const struct lfs_config *c, lfs_block_t block, lfs_off_t off, const void *buffer, lfs_size_t size)
{
    BSP_QSPI_Write((uint8_t *)buffer, (block * c->block_size + off), size);
    return 0;
}

int block_device_erase(const struct lfs_config *c, lfs_block_t block)
{
    BSP_QSPI_Erase_Block(block * c->block_size);
    return 0;
}

int block_device_sync(const struct lfs_config *c)
{
    return 0;
}

void readFile(lfs_t *lfs, lfs_file_t *file, const char *path, void *buffer, lfs_size_t size)
{
    lfs_file_open(lfs, file, path, LFS_O_RDWR | LFS_O_CREAT);
    lfs_file_read(lfs, file, buffer, size);
    lfs_file_close(lfs, file);
}

void writeFile(lfs_t *lfs, lfs_file_t *file, const char *path, const void *buffer, lfs_size_t size)
{
    lfs_file_open(lfs, file, path, LFS_O_RDWR | LFS_O_CREAT);
    lfs_file_write(lfs, file, buffer, size);
    lfs_file_close(lfs, file);
}

static int traverse_df_cb(void *p, lfs_block_t block)
{
    uint32_t *nb = p;
    *nb += 1;
    return 0;
}

static int df(void)
{
    int err;

    uint32_t df_nballocatedblock = 0;
    err = lfs_fs_traverse(&lfs, traverse_df_cb, &df_nballocatedblock);
    if (err < 0)
    {
        return err;
    }

    uint32_t available = cfg.block_count * cfg.block_size - df_nballocatedblock * cfg.block_size;

    return available;
}

int16_t GetTemperature()
{
    int8_t buffer[2];
    buffer[0] = MAGNETO_IO_Read(LSM303C_TEMP_OUT_L_M);
    buffer[1] = MAGNETO_IO_Read(LSM303C_TEMP_OUT_H_M);

    int16_t temp = ((int16_t)((uint16_t)buffer[1] << 8) + buffer[0]);
    return temp;
}

void initMagneto()
{
    MAGNETO_IO_Init();
    MAGNETO_IO_Write(LSM303C_CTRL_REG1_M, LSM303C_MAG_TEMPSENSOR_ENABLE | LSM303C_MAG_OM_XY_ULTRAHIGH | LSM303C_MAG_ODR_40_HZ);
    MAGNETO_IO_Write(LSM303C_CTRL_REG2_M, LSM303C_MAG_FS_16_GA | LSM303C_MAG_REBOOT_DEFAULT | LSM303C_MAG_SOFT_RESET_DEFAULT);
    MAGNETO_IO_Write(LSM303C_CTRL_REG3_M, 0x84);
    MAGNETO_IO_Write(LSM303C_CTRL_REG4_M, LSM303C_MAG_OM_Z_ULTRAHIGH | LSM303C_MAG_BLE_LSB);
    MAGNETO_IO_Write(LSM303C_CTRL_REG5_M, LSM303C_MAG_BDU_CONTINUOUS);
}

void initFileSystem(int *number_of_records, uint32_t *delay_between_saves)
{
    if (!lfs_mount(&lfs, &cfg))
    {
        BSP_LCD_GLASS_DisplayString((uint8_t *)"FS OK");
        readFile(&lfs, &file, "number_of_records", number_of_records, sizeof((*number_of_records)));
        readFile(&lfs, &file, "delay_between_saves", delay_between_saves, sizeof((*delay_between_saves)));
    }
    else
    {
        BSP_LCD_GLASS_DisplayString((uint8_t *)"FS NEW");
        lfs_format(&lfs, &cfg);
        lfs_mount(&lfs, &cfg);
        writeFile(&lfs, &file, "number_of_records", number_of_records, sizeof((*number_of_records)));
        writeFile(&lfs, &file, "delay_between_saves", delay_between_saves, sizeof((*delay_between_saves)));
    }
}

float convertRegDataToTemperature(int16_t value)
{
    int32_t temp = 0;
    float result;
    temp = 32768 + (int32_t)value;
    result = (((float)temp / 65535) * 120) - 40;
    return result;
}

float getTemperatureCelsius()
{
    float result = 0;
    result = convertRegDataToTemperature(GetTemperature());
    return result;
}

void menu(int *menu_position, char *text, int *menu_select, int *i, bool erase_flag)
{
    KeyPressed = RESET;
    int menu_entities = 4;

    switch (joy_state)
    {
    case JOY_UP:
        if ((*menu_select) == 0)
        {
            (*menu_position)--;

            if ((*menu_position) < 1)
            {
                (*menu_position) = menu_entities;
            }

            (*i) = 0;
        }
        break;

    case JOY_DOWN:
        if ((*menu_select) == 0)
        {
            (*menu_position)++;

            if ((*menu_position) > menu_entities)
            {
                (*menu_position) = 1;
            }

            (*i) = 0;
        }
        break;

    case JOY_LEFT:
        if (!erase_flag)
        {
            (*menu_select) = 0;
            (*i) = 0;
        }
        break;

    case JOY_SEL:
        (*menu_select) = (*menu_position);
        (*i) = 0;
        break;

    default:
        break;
    }
}

void menuUserView(int choose, char *text)
{
    switch (choose)
    {
    case 1:
        sprintf(text, "WYSWIETL AKTUALNY ODCZYT      ");
        break;
    case 2:
        sprintf(text, "WYSWIETL HISTORIE      ");
        break;
    case 3:
        sprintf(text, "USTAW DATE I GODZINE      ");
        break;
    case 4:
        sprintf(text, "USTAW CZAS POMIEDZY ZAPISAMI      ");
        break;
    }
}

void setDateUserView(int choose, RTC_TimeTypeDef time, RTC_DateTypeDef date, char *text)
{
    switch (choose)
    {
    case 0:
        sprintf(text, "D %02d", date.Date);
        break;
    case 1:
        sprintf(text, "MSC %02d", date.Month);
        break;
    case 2:
        sprintf(text, "R 20%02d", date.Year);
        break;
    case 3:
        sprintf(text, "G %02d", time.Hours);
        break;
    case 4:
        sprintf(text, "MIN %02d", time.Minutes);
        break;
    case 5:
        sprintf(text, "S %02d", time.Seconds);
        break;
    default:
        break;
    }
}

void changeDateDown(int choose, RTC_TimeTypeDef *time, RTC_DateTypeDef *date)
{
    switch (choose)
    {
    case 0:
        date->Date--;
        if (date->Date < 1)
        {
            date->Date = 31;
        }
        break;
    case 1:
        date->Month--;
        if (date->Month < 1)
        {
            date->Month = 12;
        }
        break;
    case 2:

        if (date->Year <= 0)
        {
            date->Year = 99;
        }
        else
        {
            date->Year--;
        }
        break;
    case 3:

        if (time->Hours <= 0)
        {
            time->Hours = 23;
        }
        else
        {
            time->Hours--;
        }
        break;
    case 4:

        if (time->Minutes <= 0)
        {
            time->Minutes = 59;
        }
        else
        {
            time->Minutes--;
        }
        break;
    case 5:

        if (time->Seconds <= 0)
        {
            time->Seconds = 59;
        }
        else
        {
            time->Seconds--;
        }
        break;
    default:
        break;
    }
}

void changeDateUp(int choose, RTC_TimeTypeDef *time, RTC_DateTypeDef *date)
{
    switch (choose)
    {
    case 0:
        date->Date++;
        if (date->Date > 31)
        {
            date->Date = 1;
        }
        break;
    case 1:
        date->Month++;
        if (date->Month > 12)
        {
            date->Month = 1;
        }
        break;
    case 2:
        date->Year++;
        if (date->Year > 99)
        {
            date->Year = 0;
        }
        break;
    case 3:
        time->Hours++;
        if (time->Hours > 23)
        {
            time->Hours = 0;
        }
        break;
    case 4:
        time->Minutes++;
        if (time->Minutes > 59)
        {
            time->Minutes = 0;
        }
        break;
    case 5:
        time->Seconds++;
        if (time->Seconds > 59)
        {
            time->Seconds = 0;
        }
        break;
    default:
        break;
    }
}

void timeUserView(int choose, RTC_TimeTypeDef *time, char *text)
{
    switch (choose)
    {
    case 0:
        sprintf(text, "G %02d", time->Hours);
        break;
    case 1:
        sprintf(text, "MIN %02d", time->Minutes);
        break;
    case 2:
        sprintf(text, "S %02d", time->Seconds);
        break;
    default:
        break;
    }
}

void changeTimeDown(int choose, RTC_TimeTypeDef *time)
{
    switch (choose)
    {
    case 0:

        if (time->Hours <= 0)
        {
            time->Hours = 23;
        }
        else
        {
            time->Hours--;
        }
        break;
    case 1:

        if (time->Minutes <= 0)
        {
            time->Minutes = 59;
        }
        else
        {
            time->Minutes--;
        }
        break;
    case 2:

        if (time->Seconds <= 0)
        {
            time->Seconds = 59;
        }
        else
        {
            time->Seconds--;
        }
        if (time->Seconds == 0 && (time->Minutes == 0 && time->Hours == 0))
        {
            time->Seconds = 1;
        }
        break;
    default:
        break;
    }
}

void changeTimeUp(int choose, RTC_TimeTypeDef *time)
{
    switch (choose)
    {
    case 0:
        time->Hours++;
        if (time->Hours > 23)
        {
            time->Hours = 0;
        }
        break;
    case 1:
        time->Minutes++;
        if (time->Minutes > 59)
        {
            time->Minutes = 0;
        }
        break;
    case 2:
        time->Seconds++;
        if (time->Seconds > 59)
        {
            time->Seconds = 0;
        }
        if (time->Seconds == 0 && (time->Minutes == 0 && time->Hours == 0))
        {
            time->Seconds = 1;
        }
        break;
    default:
        break;
    }
}

void setDelayBetweenSaves(uint32_t *delay_between_saves, RTC_TimeTypeDef *time)
{
    (*delay_between_saves) = time->Hours * 3600000 + time->Minutes * 60000 + time->Seconds * 1000;
    writeFile(&lfs, &file, "delay_between_saves", delay_between_saves, sizeof(delay_between_saves));
}

bool eraseAllData(int *number_of_records, int *read_record_number, uint32_t *delay_between_saves)
{
    lfs_unmount(&lfs);
    lfs_format(&lfs, &cfg);
    lfs_mount(&lfs, &cfg);
    (*number_of_records) = 0;
    writeFile(&lfs, &file, "number_of_records", number_of_records, sizeof(number_of_records));
    writeFile(&lfs, &file, "delay_between_saves", delay_between_saves, sizeof(delay_between_saves));
    (*read_record_number) = 1;

    return false;
}

void viewActualData(RTC_TimeTypeDef *RtcTime, RTC_DateTypeDef *RtcDate, char *text)
{
    float int_part, fract_part;
    HAL_RTC_GetTime(&hrtc, RtcTime, RTC_FORMAT_BIN);
    HAL_RTC_GetDate(&hrtc, RtcDate, RTC_FORMAT_BIN);
    fract_part = modff(getTemperatureCelsius(), &int_part);
    sprintf((char *)text, "D %02d/%02d/%02d T %02d-%02d-%02d TEMP %d %01d*C      ",
            RtcDate->Date, RtcDate->Month, RtcDate->Year, RtcTime->Hours, RtcTime->Minutes, RtcTime->Seconds, (int)int_part, (int)(fract_part * 10.0));
}

void saveData(RTC_TimeTypeDef *RtcTime, RTC_DateTypeDef *RtcDate, int *number_of_records)
{
    float int_part, fract_part;
    char record_file_name[15], text[60];
    HAL_RTC_GetTime(&hrtc, RtcTime, RTC_FORMAT_BIN);
    HAL_RTC_GetDate(&hrtc, RtcDate, RTC_FORMAT_BIN);
    fract_part = modff(getTemperatureCelsius(), &int_part);
    sprintf((char *)text, "D %02d/%02d/%02d T %02d-%02d-%02d TEMP %d %01d*C      ",
            RtcDate->Date, RtcDate->Month, RtcDate->Year, RtcTime->Hours, RtcTime->Minutes, RtcTime->Seconds, (int)int_part, (int)(fract_part * 10.0));
    if (df() > 0)
    {
        (*number_of_records)++;
        sprintf(record_file_name, "record%d", (*number_of_records));
        writeFile(&lfs, &file, record_file_name, text, sizeof(text));
        writeFile(&lfs, &file, "number_of_records", number_of_records, sizeof(number_of_records));
    }
    else
    {
        BSP_LCD_GLASS_Clear();
        BSP_LCD_GLASS_DisplayString((char *)"FULL");
        HAL_Delay(1000);
    }
}

void setTimeBetweenSaves(RTC_TimeTypeDef *time, uint32_t delay)
{
    time->Seconds = (delay % 60000) / 1000;
    time->Minutes = ((delay % 3600000) / 1000 - time->Seconds) / 60;
    time->Hours = (delay / 1000 - time->Minutes * 60 - time->Seconds) / 3600;
}
/* USER CODE END 4 */

void Error_Handler(void)
{
    __disable_irq();
    while (1)
    {
    }
}
